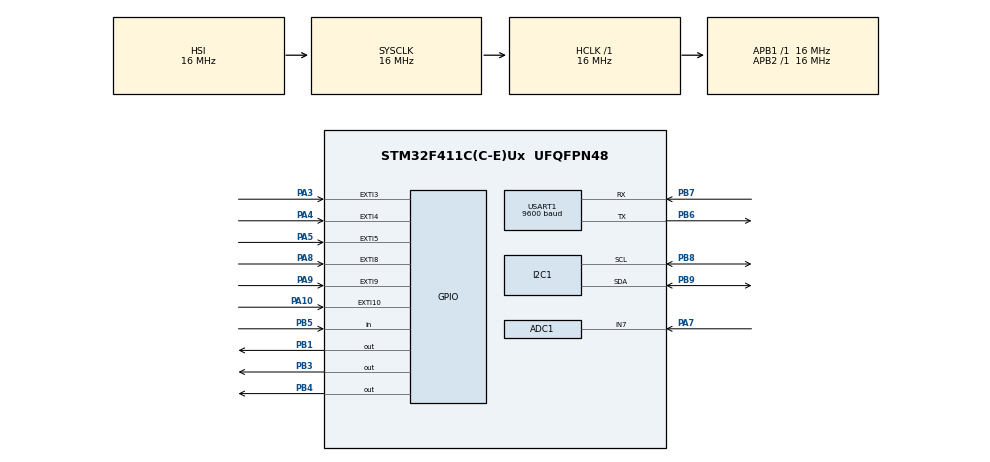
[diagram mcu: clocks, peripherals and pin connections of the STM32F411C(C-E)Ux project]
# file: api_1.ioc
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ADC1.Channel-0\#ChannelRegularConversion=ADC_CHANNEL_7
ADC1.NbrOfConversionFlag=1
ADC1.Rank-0\#ChannelRegularConversion=1
ADC1.SamplingTime-0\#ChannelRegularConversion=ADC_SAMPLETIME_3CYCLES
ADC1.master=1
Mcu.Family=STM32F4
Mcu.Name=STM32F411C(C-E)Ux
Mcu.Package=UFQFPN48
NVIC.EXTI15_10_IRQn=true\:0\:0\:false\:false\:true\:true\:true\:true
NVIC.EXTI3_IRQn=true\:0\:0\:false\:false\:true\:true\:true\:true
NVIC.EXTI4_IRQn=true\:0\:0\:false\:false\:true\:true\:true\:true
NVIC.EXTI9_5_IRQn=true\:0\:0\:false\:false\:true\:true\:true\:true
NVIC.PriorityGroup=NVIC_PRIORITYGROUP_4
PA10.GPIO_ModeDefaultEXTI=GPIO_MODE_IT_FALLING
PA10.GPIO_PuPd=GPIO_PULLUP
PA10.Signal=GPXTI10
PA13.Signal=SYS_JTMS-SWDIO
PA14.Signal=SYS_JTCK-SWCLK
PA3.GPIO_ModeDefaultEXTI=GPIO_MODE_IT_FALLING
PA3.GPIO_PuPd=GPIO_PULLUP
PA3.Signal=GPXTI3
PA4.GPIO_ModeDefaultEXTI=GPIO_MODE_IT_FALLING
PA4.GPIO_PuPd=GPIO_PULLUP
PA4.Signal=GPXTI4
PA5.GPIO_ModeDefaultEXTI=GPIO_MODE_IT_FALLING
PA5.GPIO_PuPd=GPIO_PULLUP
PA5.Signal=GPXTI5
PA7.Signal=ADCx_IN7
PA8.GPIO_ModeDefaultEXTI=GPIO_MODE_IT_FALLING
PA8.GPIO_PuPd=GPIO_PULLUP
PA8.Signal=GPXTI8
PA9.GPIO_ModeDefaultEXTI=GPIO_MODE_IT_FALLING
PA9.GPIO_PuPd=GPIO_PULLUP
PA9.Signal=GPXTI9
PB1.Signal=GPIO_Output
PB3.Signal=GPIO_Output
PB4.Signal=GPIO_Output
PB5.GPIO_PuPd=GPIO_PULLUP
PB5.Signal=GPIO_Input
PB6.Mode=Asynchronous
PB6.Signal=USART1_TX
PB7.Mode=Asynchronous
PB7.Signal=USART1_RX
PB8.Mode=I2C
PB8.Signal=I2C1_SCL
PB9.Mode=I2C
PB9.Signal=I2C1_SDA
ProjectManager.HeapSize=0x200
ProjectManager.StackSize=0x400
ProjectManager.TargetToolchain=STM32CubeIDE
RCC.AHBFreq_Value=16000000
RCC.APB1Freq_Value=16000000
RCC.APB2Freq_Value=16000000
RCC.CortexFreq_Value=16000000
RCC.HSE_VALUE=25000000
RCC.HSI_VALUE=16000000
RCC.LSE_VALUE=32768
RCC.SYSCLKFreq_VALUE=16000000
RCC.VCOOutputFreq_Value=192000000
SH.ADCx_IN7.0=ADC1_IN7,IN7
USART1.BaudRate=9600
USART1.VirtualMode=VM_ASYNC
board=custom

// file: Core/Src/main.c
/* USER CODE BEGIN Header */
/**
  ******************************************************************************
  * @file           : main.c
  * @brief          : Main program body
  ******************************************************************************
  * @attention
  *
  * Copyright (c) 2026 STMicroelectronics.
  * All rights reserved.
  *
  * This software is licensed under terms that can be found in the LICENSE file
  * in the root directory of this software component.
  * If no LICENSE file comes with this software, it is provided AS-IS.
  *
  ******************************************************************************
  */
/* USER CODE END Header */
#include "main.h"

/* USER CODE BEGIN Includes */
#include "app.h"
/* USER CODE END Includes */

ADC_HandleTypeDef hadc1;

I2C_HandleTypeDef hi2c1;

UART_HandleTypeDef huart1;

void SystemClock_Config(void);
static void MX_GPIO_Init(void);
static void MX_I2C1_Init(void);
static void MX_USART1_UART_Init(void);
static void MX_ADC1_Init(void);

int main(void)
{

  /* MCU Configuration--------------------------------------------------------*/

  /* Reset of all peripherals, Initializes the Flash interface and the Systick. */
  HAL_Init();

  /* Configure the system clock */
  SystemClock_Config();

  /* Initialize all configured peripherals */
  MX_GPIO_Init();
  MX_I2C1_Init();
  MX_USART1_UART_Init();
  MX_ADC1_Init();
  /* USER CODE BEGIN 2 */
  App_Init(&huart1);
  /* USER CODE END 2 */

  /* Infinite loop */
  /* USER CODE BEGIN WHILE */
  while (1)
  {
	  App_Loop();

    /* USER CODE END WHILE */

  }
}

void SystemClock_Config(void)
{
  RCC_OscInitTypeDef RCC_OscInitStruct = {0};
  RCC_ClkInitTypeDef RCC_ClkInitStruct = {0};

  /** Configure the main internal regulator output voltage
  */
  __HAL_RCC_PWR_CLK_ENABLE();
  __HAL_PWR_VOLTAGESCALING_CONFIG(PWR_REGULATOR_VOLTAGE_SCALE1);

  /** Initializes the RCC Oscillators according to the specified parameters
  * in the RCC_OscInitTypeDef structure.
  */
  RCC_OscInitStruct.OscillatorType = RCC_OSCILLATORTYPE_HSI;
  RCC_OscInitStruct.HSIState = RCC_HSI_ON;
  RCC_OscInitStruct.HSICalibrationValue = RCC_HSICALIBRATION_DEFAULT;
  RCC_OscInitStruct.PLL.PLLState = RCC_PLL_NONE;
  if (HAL_RCC_OscConfig(&RCC_OscInitStruct) != HAL_OK)
  {
    Error_Handler();
  }

  /** Initializes the CPU, AHB and APB buses clocks
  */
  RCC_ClkInitStruct.ClockType = RCC_CLOCKTYPE_HCLK|RCC_CLOCKTYPE_SYSCLK
                              |RCC_CLOCKTYPE_PCLK1|RCC_CLOCKTYPE_PCLK2;
  RCC_ClkInitStruct.SYSCLKSource = RCC_SYSCLKSOURCE_HSI;
  RCC_ClkInitStruct.AHBCLKDivider = RCC_SYSCLK_DIV1;
  RCC_ClkInitStruct.APB1CLKDivider = RCC_HCLK_DIV1;
  RCC_ClkInitStruct.APB2CLKDivider = RCC_HCLK_DIV1;

  if (HAL_RCC_ClockConfig(&RCC_ClkInitStruct, FLASH_LATENCY_0) != HAL_OK)
  {
    Error_Handler();
  }
}

static void MX_ADC1_Init(void)
{

  ADC_ChannelConfTypeDef sConfig = {0};

  /** Configure the global features of the ADC (Clock, Resolution, Data Alignment and number of conversion)
  */
  hadc1.Instance = ADC1;
  hadc1.Init.ClockPrescaler = ADC_CLOCK_SYNC_PCLK_DIV2;
  hadc1.Init.Resolution = ADC_RESOLUTION_12B;
  hadc1.Init.ScanConvMode = DISABLE;
  hadc1.Init.ContinuousConvMode = DISABLE;
  hadc1.Init.DiscontinuousConvMode = DISABLE;
  hadc1.Init.ExternalTrigConvEdge = ADC_EXTERNALTRIGCONVEDGE_NONE;
  hadc1.Init.ExternalTrigConv = ADC_SOFTWARE_START;
  hadc1.Init.DataAlign = ADC_DATAALIGN_RIGHT;
  hadc1.Init.NbrOfConversion = 1;
  hadc1.Init.DMAContinuousRequests = DISABLE;
  hadc1.Init.EOCSelection = ADC_EOC_SINGLE_CONV;
  if (HAL_ADC_Init(&hadc1) != HAL_OK)
  {
    Error_Handler();
  }

  /** Configure for the selected ADC regular channel its corresponding rank in the sequencer and its sample time.
  */
  sConfig.Channel = ADC_CHANNEL_7;
  sConfig.Rank = 1;
  sConfig.SamplingTime = ADC_SAMPLETIME_3CYCLES;
  if (HAL_ADC_ConfigChannel(&hadc1, &sConfig) != HAL_OK)
  {
    Error_Handler();
  }

}

static void MX_I2C1_Init(void)
{

  hi2c1.Instance = I2C1;
  hi2c1.Init.ClockSpeed = 100000;
  hi2c1.Init.DutyCycle = I2C_DUTYCYCLE_2;
  hi2c1.Init.OwnAddress1 = 0;
  hi2c1.Init.AddressingMode = I2C_ADDRESSINGMODE_7BIT;
  hi2c1.Init.DualAddressMode = I2C_DUALADDRESS_DISABLE;
  hi2c1.Init.OwnAddress2 = 0;
  hi2c1.Init.GeneralCallMode = I2C_GENERALCALL_DISABLE;
  hi2c1.Init.NoStretchMode = I2C_NOSTRETCH_DISABLE;
  if (HAL_I2C_Init(&hi2c1) != HAL_OK)
  {
    Error_Handler();
  }

}

static void MX_USART1_UART_Init(void)
{

  huart1.Instance = USART1;
  huart1.Init.BaudRate = 9600;
  huart1.Init.WordLength = UART_WORDLENGTH_8B;
  huart1.Init.StopBits = UART_STOPBITS_1;
  huart1.Init.Parity = UART_PARITY_NONE;
  huart1.Init.Mode = UART_MODE_TX_RX;
  huart1.Init.HwFlowCtl = UART_HWCONTROL_NONE;
  huart1.Init.OverSampling = UART_OVERSAMPLING_16;
  if (HAL_UART_Init(&huart1) != HAL_OK)
  {
    Error_Handler();
  }

}

static void MX_GPIO_Init(void)
{
  GPIO_InitTypeDef GPIO_InitStruct = {0};

  /* GPIO Ports Clock Enable */
  __HAL_RCC_GPIOA_CLK_ENABLE();
  __HAL_RCC_GPIOB_CLK_ENABLE();

  /*Configure GPIO pin Output Level */
  HAL_GPIO_WritePin(GPIOB, GPIO_PIN_1|GPIO_PIN_3|GPIO_PIN_4, GPIO_PIN_RESET);

  /*Configure GPIO pins : PA3 PA4 PA5 PA8
                           PA9 PA10 */
  GPIO_InitStruct.Pin = GPIO_PIN_3|GPIO_PIN_4|GPIO_PIN_5|GPIO_PIN_8
                          |GPIO_PIN_9|GPIO_PIN_10;
  GPIO_InitStruct.Mode = GPIO_MODE_IT_FALLING;
  GPIO_InitStruct.Pull = GPIO_PULLUP;
  HAL_GPIO_Init(GPIOA, &GPIO_InitStruct);

  /*Configure GPIO pins : PB1 PB3 PB4 */
  GPIO_InitStruct.Pin = GPIO_PIN_1|GPIO_PIN_3|GPIO_PIN_4;
  GPIO_InitStruct.Mode = GPIO_MODE_OUTPUT_PP;
  GPIO_InitStruct.Pull = GPIO_NOPULL;
  GPIO_InitStruct.Speed = GPIO_SPEED_FREQ_LOW;
  HAL_GPIO_Init(GPIOB, &GPIO_InitStruct);

  /*Configure GPIO pin : PB5 */
  GPIO_InitStruct.Pin = GPIO_PIN_5;
  GPIO_InitStruct.Mode = GPIO_MODE_INPUT;
  GPIO_InitStruct.Pull = GPIO_PULLUP;
  HAL_GPIO_Init(GPIOB, &GPIO_InitStruct);

  /* EXTI interrupt init*/
  HAL_NVIC_SetPriority(EXTI3_IRQn, 0, 0);
  HAL_NVIC_EnableIRQ(EXTI3_IRQn);

  HAL_NVIC_SetPriority(EXTI4_IRQn, 0, 0);
  HAL_NVIC_EnableIRQ(EXTI4_IRQn);

  HAL_NVIC_SetPriority(EXTI9_5_IRQn, 0, 0);
  HAL_NVIC_EnableIRQ(EXTI9_5_IRQn);

  HAL_NVIC_SetPriority(EXTI15_10_IRQn, 0, 0);
  HAL_NVIC_EnableIRQ(EXTI15_10_IRQn);

}

void Error_Handler(void)
{
  __disable_irq();
  while (1)
  {
  }
}
